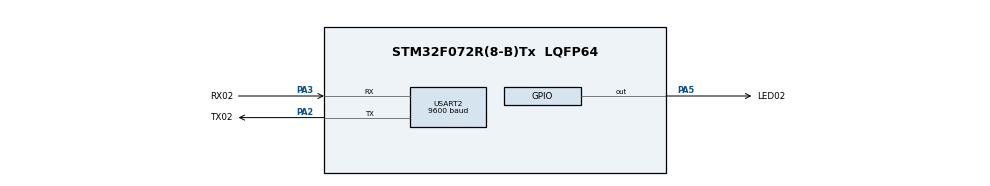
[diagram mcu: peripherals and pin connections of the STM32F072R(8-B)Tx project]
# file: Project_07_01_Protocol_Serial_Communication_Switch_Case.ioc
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Mcu.Family=STM32F0
Mcu.Name=STM32F072R(8-B)Tx
Mcu.Package=LQFP64
NVIC.USART2_IRQn=true\:0\:0\:false\:false\:true\:true\:true\:true
PA2.GPIO_Label=TX02
PA2.Mode=Asynchronous
PA2.Signal=USART2_TX
PA3.GPIO_Label=RX02
PA3.Mode=Asynchronous
PA3.Signal=USART2_RX
PA5.GPIO_Label=LED02
PA5.Signal=GPIO_Output
ProjectManager.HeapSize=0x200
ProjectManager.StackSize=0x400
ProjectManager.TargetToolchain=STM32CubeIDE
USART2.BaudRate=9600
USART2.VirtualMode-Asynchronous=VM_ASYNC
board=custom

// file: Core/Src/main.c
/* USER CODE BEGIN Header */
/**
  ******************************************************************************
  * @file           : main.c
  * @brief          : Main program body
  ******************************************************************************
  * @attention
  *
  * Copyright (c) 2022 STMicroelectronics.
  * All rights reserved.
  *
  * This software is licensed under terms that can be found in the LICENSE file
  * in the root directory of this software component.
  * If no LICENSE file comes with this software, it is provided AS-IS.
  *
  ******************************************************************************
  */
/* USER CODE END Header */
#include "main.h"

/* USER CODE BEGIN Includes */
#include <stdlib.h>
#include <stdio.h>

/* USER CODE END Includes */

/* USER CODE BEGIN PD */

#define comand_high  HAL_GPIO_WritePin(GPIOA,GPIO_PIN_5,GPIO_PIN_SET)
#define comand_low HAL_GPIO_WritePin(GPIOA,GPIO_PIN_5,GPIO_PIN_RESET)
#define delay_00 HAL_Delay(750)
#define delay_01 HAL_Delay(450)

#define comand_high  HAL_GPIO_WritePin(GPIOA,GPIO_PIN_5,GPIO_PIN_SET)
#define comand_low HAL_GPIO_WritePin(GPIOA,GPIO_PIN_5,GPIO_PIN_RESET)
#define delay_00 HAL_Delay(750)
#define delay_01 HAL_Delay(450)
#define ESTAGIO_PREPROSSEAMENTO 0
#define ESTAGIO_01 1
#define ESTAGIO_02 2
#define ESTAGIO_03 3
#define ESTAGIO_04 4
#define ESTAGIO_05 5

/* USER CODE END PD */

UART_HandleTypeDef huart2;

/* USER CODE BEGIN PV */

volatile char v_controle;

/* USER CODE END PV */

void SystemClock_Config(void);
static void MX_GPIO_Init(void);
static void MX_USART2_UART_Init(void);
/* USER CODE BEGIN PFP */

int  pisca_led (int NumPiscadas, int TempoDelay)
{
	//pesquisar sobre funções, e qual é a diferença da uma fuunção void para uma int, char....

	for (int i = 0; i <= NumPiscadas; i++)
	{

		HAL_GPIO_WritePin(GPIOA,LED02_Pin,GPIO_PIN_SET);
		HAL_Delay(TempoDelay);
		HAL_GPIO_WritePin(GPIOA,LED02_Pin,GPIO_PIN_RESET);
		HAL_Delay(TempoDelay);

	}

	return 0;

}

void Protocolo(uint8_t *a)
{
//Quan a função é declarada e logo abaixo é chamda não é necessário montar um projeto

	  fflush(stdin);

	  //uint8_t rec_bit[] = "\r\n\n !\r\n\n";
	  uint8_t erro_bit[] = "\r\n\n Dado incorreta!\r\n";
	  uint8_t msg_00[] = "Estagio de espera concluido!!\r\n";
	  uint8_t msg_01[] = "Estagio 1 concluido!!\r\n";
	  uint8_t msg_02[] = "Estagio 2 concluido!!\r\n";
	  uint8_t msg_03[] = "Estagio 3 concluido!!\r\n";
	  uint8_t msg_04[] = "Estagio 4 concluido!!\r\n";
	  uint8_t Pula_linha[] = "\n";

	  switch(v_controle)
	  {

		  case ESTAGIO_PREPROSSEAMENTO:
		  {

			  if((a[0] == 'L')){

				v_controle  = ESTAGIO_01;

				HAL_UART_Transmit(&huart2,msg_00,sizeof(msg_00)-1,100);
				HAL_UART_Transmit(&huart2,&a[0],1,100);
				HAL_UART_Transmit(&huart2,Pula_linha,sizeof(Pula_linha),100);

			  }

			  if ((a[0] != 'L' ) && (a[0] != '\0') )
			  {

				  HAL_UART_Transmit(&huart2,erro_bit,sizeof(erro_bit)-1,100);
				  break;

			  }

		  }

		  case ESTAGIO_01:
		  {

			  if((a[1] == 'U'))
			  {

				v_controle  = ESTAGIO_02;

				HAL_UART_Transmit(&huart2,msg_01,sizeof(msg_01)-1,100);
				HAL_UART_Transmit(&huart2,&a[1],1,100);
				HAL_UART_Transmit(&huart2,Pula_linha,sizeof(Pula_linha),100);

			  }

			  if ((a[1] != 'U') && (a[1] != '\0'))
			  {

				  HAL_UART_Transmit(&huart2,erro_bit,sizeof(erro_bit)-1,100);
				  break;

			  }

		  }

		  case ESTAGIO_02:
		  {

			  if((a[2] == 'P'))
			  {

				v_controle  = ESTAGIO_03;

				HAL_UART_Transmit(&huart2,msg_02,sizeof(msg_02)-1,100);
				HAL_UART_Transmit(&huart2,&a[2],1,100);
				HAL_UART_Transmit(&huart2,Pula_linha,sizeof(Pula_linha),100);

			  }

			  if ((a[2] != 'P') && (a[2] != '\0'))
			  {

				  HAL_UART_Transmit(&huart2,erro_bit,sizeof(erro_bit)-1,100);
				  break;

			  }

		  }

		  case ESTAGIO_03:
		  {

			  if((a[3] == 'A'))
			  {

				v_controle  = ESTAGIO_03;

				HAL_UART_Transmit(&huart2,msg_03,sizeof(msg_03)-1,100);
				HAL_UART_Transmit(&huart2,&a[3],1,100);
				HAL_UART_Transmit(&huart2,Pula_linha,sizeof(Pula_linha),100);

			  }

			  if ((a[3] != 'A') && (a[3] != '\0'))
			  {

				  HAL_UART_Transmit(&huart2,erro_bit,sizeof(erro_bit)-1,100);
				  break;

			  }

		  }

		  case ESTAGIO_04:
		  {

			  if((a[4] == 'H'))
			  {

				v_controle  = ESTAGIO_PREPROSSEAMENTO;

				HAL_UART_Transmit(&huart2,msg_04,sizeof(msg_04)-1,100);
				HAL_UART_Transmit(&huart2,&a[4],1,100);
				HAL_UART_Transmit(&huart2,Pula_linha,sizeof(Pula_linha),100);
				pisca_led(5,250);

			  }

			  if ((a[4] != 'H') && (a[4] != '\0'))
			  {

				  HAL_UART_Transmit(&huart2,erro_bit,sizeof(erro_bit)-1,100);
				  break;

			  }

		  }

		  HAL_UART_Transmit(&huart2,a,5,100);
		  HAL_UART_Transmit(&huart2,Pula_linha,sizeof(Pula_linha),100);

		  for (int i = 0; i < 6 ;i++)

		  {

			  a[i] = 0;

		  }

	  }

}

/* USER CODE END PFP */

int main(void)
{
  /* USER CODE BEGIN 1 */
	v_controle  = ESTAGIO_PREPROSSEAMENTO;

   uint8_t rx_buffer[20] = {0};
   HAL_StatusTypeDef status;

  /* USER CODE END 1 */

  /* MCU Configuration--------------------------------------------------------*/

  /* Reset of all peripherals, Initializes the Flash interface and the Systick. */
  HAL_Init();

  /* Configure the system clock */
  SystemClock_Config();

  /* Initialize all configured peripherals */
  MX_GPIO_Init();
  MX_USART2_UART_Init();

  /* Infinite loop */
  while (1)
  {

		 status  =  HAL_UART_Receive_IT(&huart2,rx_buffer,20);
		 //status  = HAL_UART_Receive(&huart2, rx_buffer, sizeof(rx_buffer), 100);
		 HAL_Delay(1000);

		 if (status == HAL_OK)

		 {

		  Protocolo(rx_buffer);

		 }

  }
}

void SystemClock_Config(void)
{
  RCC_OscInitTypeDef RCC_OscInitStruct = {0};
  RCC_ClkInitTypeDef RCC_ClkInitStruct = {0};
  RCC_PeriphCLKInitTypeDef PeriphClkInit = {0};

  /** Initializes the RCC Oscillators according to the specified parameters
  * in the RCC_OscInitTypeDef structure.
  */
  RCC_OscInitStruct.OscillatorType = RCC_OSCILLATORTYPE_HSI;
  RCC_OscInitStruct.HSIState = RCC_HSI_ON;
  RCC_OscInitStruct.HSICalibrationValue = RCC_HSICALIBRATION_DEFAULT;
  RCC_OscInitStruct.PLL.PLLState = RCC_PLL_NONE;
  if (HAL_RCC_OscConfig(&RCC_OscInitStruct) != HAL_OK)
  {
    Error_Handler();
  }

  /** Initializes the CPU, AHB and APB buses clocks
  */
  RCC_ClkInitStruct.ClockType = RCC_CLOCKTYPE_HCLK|RCC_CLOCKTYPE_SYSCLK
                              |RCC_CLOCKTYPE_PCLK1;
  RCC_ClkInitStruct.SYSCLKSource = RCC_SYSCLKSOURCE_HSI;
  RCC_ClkInitStruct.AHBCLKDivider = RCC_SYSCLK_DIV1;
  RCC_ClkInitStruct.APB1CLKDivider = RCC_HCLK_DIV1;

  if (HAL_RCC_ClockConfig(&RCC_ClkInitStruct, FLASH_LATENCY_0) != HAL_OK)
  {
    Error_Handler();
  }
  PeriphClkInit.PeriphClockSelection = RCC_PERIPHCLK_USART2;
  PeriphClkInit.Usart2ClockSelection = RCC_USART2CLKSOURCE_PCLK1;
  if (HAL_RCCEx_PeriphCLKConfig(&PeriphClkInit) != HAL_OK)
  {
    Error_Handler();
  }
}

static void MX_USART2_UART_Init(void)
{

  huart2.Instance = USART2;
  huart2.Init.BaudRate = 9600;
  huart2.Init.WordLength = UART_WORDLENGTH_8B;
  huart2.Init.StopBits = UART_STOPBITS_1;
  huart2.Init.Parity = UART_PARITY_NONE;
  huart2.Init.Mode = UART_MODE_TX_RX;
  huart2.Init.HwFlowCtl = UART_HWCONTROL_NONE;
  huart2.Init.OverSampling = UART_OVERSAMPLING_16;
  huart2.Init.OneBitSampling = UART_ONE_BIT_SAMPLE_DISABLE;
  huart2.AdvancedInit.AdvFeatureInit = UART_ADVFEATURE_NO_INIT;
  if (HAL_UART_Init(&huart2) != HAL_OK)
  {
    Error_Handler();
  }

}

static void MX_GPIO_Init(void)
{
  GPIO_InitTypeDef GPIO_InitStruct = {0};

  /* GPIO Ports Clock Enable */
  __HAL_RCC_GPIOA_CLK_ENABLE();

  /*Configure GPIO pin Output Level */
  HAL_GPIO_WritePin(LED02_GPIO_Port, LED02_Pin, GPIO_PIN_RESET);

  /*Configure GPIO pin : LED02_Pin */
  GPIO_InitStruct.Pin = LED02_Pin;
  GPIO_InitStruct.Mode = GPIO_MODE_OUTPUT_PP;
  GPIO_InitStruct.Pull = GPIO_NOPULL;
  GPIO_InitStruct.Speed = GPIO_SPEED_FREQ_LOW;
  HAL_GPIO_Init(LED02_GPIO_Port, &GPIO_InitStruct);

}

void Error_Handler(void)
{
  __disable_irq();
  while (1)
  {
  }
}
